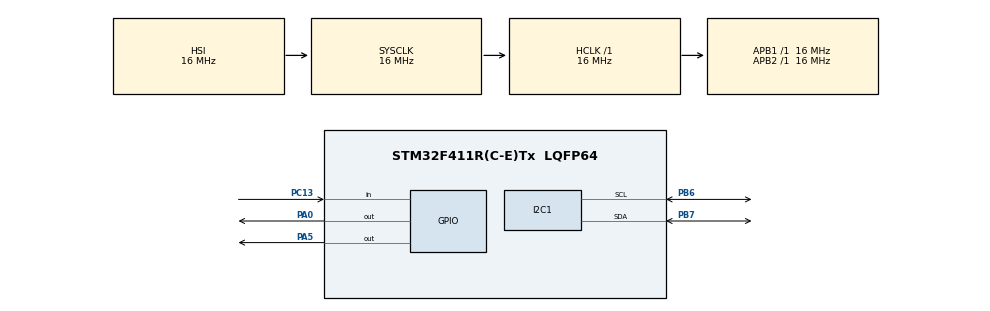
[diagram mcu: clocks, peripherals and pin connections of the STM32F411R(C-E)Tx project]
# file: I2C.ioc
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I2C1.AddressingMode=I2C_ADDRESSINGMODE_10BIT
I2C1.DutyCycle=I2C_DUTYCYCLE_16_9
I2C1.I2C_Mode=I2C_Fast
Mcu.Family=STM32F4
Mcu.Name=STM32F411R(C-E)Tx
Mcu.Package=LQFP64
NVIC.I2C1_ER_IRQn=true\:0\:0\:false
NVIC.I2C1_EV_IRQn=true\:0\:0\:false
NVIC.PriorityGroup=NVIC_PRIORITYGROUP_4
PA0-WKUP.GPIO_Speed=GPIO_SPEED_HIGH
PA0-WKUP.Signal=GPIO_Output
PA5.GPIO_Speed=GPIO_SPEED_HIGH
PA5.Signal=GPIO_Output
PB6.Mode=I2C
PB6.Signal=I2C1_SCL
PB7.Mode=I2C
PB7.Signal=I2C1_SDA
PC13-ANTI_TAMP.Signal=GPIO_Input
PH0\ -\ OSC_IN.Mode=HSE-External-Oscillator
PH0\ -\ OSC_IN.Signal=RCC_OSC_IN
PH1\ -\ OSC_OUT.Mode=HSE-External-Oscillator
PH1\ -\ OSC_OUT.Signal=RCC_OSC_OUT
ProjectManager.HeapSize=0x400
ProjectManager.StackSize=0x200
ProjectManager.TargetToolchain=MDK-ARM V5
RCC.AHBFreq_Value=16000000
RCC.APB1Freq_Value=16000000
RCC.APB2Freq_Value=16000000
RCC.CortexFreq_Value=16000000
RCC.HSE_VALUE=25000000
RCC.HSI_VALUE=16000000
RCC.LSE_VALUE=32768
RCC.SYSCLKFreq_VALUE=16000000
RCC.VCOOutputFreq_Value=192000000
board=I2C

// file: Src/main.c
/**
  ******************************************************************************
  * File Name          : main.c
  * Description        : Main program body
  ******************************************************************************
  *
  * COPYRIGHT(c) 2016 STMicroelectronics
  *
  * Redistribution and use in source and binary forms, with or without modification,
  * are permitted provided that the following conditions are met:
  *   1. Redistributions of source code must retain the above copyright notice,
  *      this list of conditions and the following disclaimer.
  *   2. Redistributions in binary form must reproduce the above copyright notice,
  *      this list of conditions and the following disclaimer in the documentation
  *      and/or other materials provided with the distribution.
  *   3. Neither the name of STMicroelectronics nor the names of its contributors
  *      may be used to endorse or promote products derived from this software
  *      without specific prior written permission.
  *
  * THIS SOFTWARE IS PROVIDED BY THE COPYRIGHT HOLDERS AND CONTRIBUTORS "AS IS"
  * AND ANY EXPRESS OR IMPLIED WARRANTIES, INCLUDING, BUT NOT LIMITED TO, THE
  * IMPLIED WARRANTIES OF MERCHANTABILITY AND FITNESS FOR A PARTICULAR PURPOSE ARE
  * DISCLAIMED. IN NO EVENT SHALL THE COPYRIGHT HOLDER OR CONTRIBUTORS BE LIABLE
  * FOR ANY DIRECT, INDIRECT, INCIDENTAL, SPECIAL, EXEMPLARY, OR CONSEQUENTIAL
  * DAMAGES (INCLUDING, BUT NOT LIMITED TO, PROCUREMENT OF SUBSTITUTE GOODS OR
  * SERVICES; LOSS OF USE, DATA, OR PROFITS; OR BUSINESS INTERRUPTION) HOWEVER
  * CAUSED AND ON ANY THEORY OF LIABILITY, WHETHER IN CONTRACT, STRICT LIABILITY,
  * OR TORT (INCLUDING NEGLIGENCE OR OTHERWISE) ARISING IN ANY WAY OUT OF THE USE
  * OF THIS SOFTWARE, EVEN IF ADVISED OF THE POSSIBILITY OF SUCH DAMAGE.
  *
  ******************************************************************************
  */
#include "stm32f4xx_hal.h"

I2C_HandleTypeDef hi2c1;

/* USER CODE BEGIN PV */
/* Private variables ---------------------------------------------------------*/
//#define MASTER_BOARD
#define I2C_ADDRESS			0x30F  // 0010 0000
uint8_t aTxBuffer[] = "Test I2C Communication";

uint8_t aRxBuffer[100];
/* USER CODE END PV */

void SystemClock_Config(void);
static void MX_GPIO_Init(void);
static void MX_I2C1_Init(void);

/* USER CODE BEGIN PFP */
/* Private function prototypes -----------------------------------------------*/

/* USER CODE END PFP */

int main(void)
{

  /* MCU Configuration----------------------------------------------------------*/

  /* Reset of all peripherals, Initializes the Flash interface and the Systick. */
  HAL_Init();

  /* Configure the system clock */
  SystemClock_Config();

  /* Initialize all configured peripherals */
  MX_GPIO_Init();
  MX_I2C1_Init();

  /* USER CODE BEGIN 2 */
/*
#ifdef MASTER_BOARD

	while(HAL_GPIO_ReadPin(GPIOC, GPIO_PIN_13) != 1)
	{
	}
	while(HAL_GPIO_ReadPin(GPIOC, GPIO_PIN_13) != 0)
	{
	}

	// Start the transmission process
	while(HAL_I2C_Master_Transmit(&hi2c1, (uint16_t)I2C_ADDRESS, (uint8_t *)aTxBuffer, 22, 10000) != HAL_OK)
	{
	}
	// turn on Led if transfer in transmission process in correct
	HAL_GPIO_WritePin(GPIOA, GPIO_PIN_0,  GPIO_PIN_RESET);
#else
*/
	// The board receives the message and sends it back
	if(HAL_I2C_Slave_Receive(&hi2c1, (uint8_t *)aRxBuffer, 22, 10000) != HAL_OK)
	{
		HAL_GPIO_WritePin(GPIOA, GPIO_PIN_0,  GPIO_PIN_SET);
	}
	HAL_GPIO_WritePin(GPIOA, GPIO_PIN_0,  GPIO_PIN_RESET);

//#endif
  /* USER CODE END 2 */

  /* Infinite loop */
  while (1)
  {
		HAL_I2C_Slave_Receive(&hi2c1, (uint8_t *)aRxBuffer, 22, 10000);

  }

}

/** System Clock Configuration
*/
void SystemClock_Config(void)
{

  RCC_OscInitTypeDef RCC_OscInitStruct;
  RCC_ClkInitTypeDef RCC_ClkInitStruct;

  __PWR_CLK_ENABLE();

  __HAL_PWR_VOLTAGESCALING_CONFIG(PWR_REGULATOR_VOLTAGE_SCALE1);

  RCC_OscInitStruct.OscillatorType = RCC_OSCILLATORTYPE_HSI;
  RCC_OscInitStruct.HSIState = RCC_HSI_ON;
  RCC_OscInitStruct.HSICalibrationValue = 16;
  RCC_OscInitStruct.PLL.PLLState = RCC_PLL_NONE;
  HAL_RCC_OscConfig(&RCC_OscInitStruct);

  RCC_ClkInitStruct.ClockType = RCC_CLOCKTYPE_HCLK|RCC_CLOCKTYPE_SYSCLK
                              |RCC_CLOCKTYPE_PCLK1|RCC_CLOCKTYPE_PCLK2;
  RCC_ClkInitStruct.SYSCLKSource = RCC_SYSCLKSOURCE_HSI;
  RCC_ClkInitStruct.AHBCLKDivider = RCC_SYSCLK_DIV1;
  RCC_ClkInitStruct.APB1CLKDivider = RCC_HCLK_DIV1;
  RCC_ClkInitStruct.APB2CLKDivider = RCC_HCLK_DIV1;
  HAL_RCC_ClockConfig(&RCC_ClkInitStruct, FLASH_LATENCY_0);

  HAL_SYSTICK_Config(HAL_RCC_GetHCLKFreq()/1000);

  HAL_SYSTICK_CLKSourceConfig(SYSTICK_CLKSOURCE_HCLK);

  /* SysTick_IRQn interrupt configuration */
  HAL_NVIC_SetPriority(SysTick_IRQn, 0, 0);
}

/* I2C1 init function */
void MX_I2C1_Init(void)
{

  hi2c1.Instance = I2C1;
  hi2c1.Init.ClockSpeed = 400000;
  hi2c1.Init.DutyCycle = I2C_DUTYCYCLE_16_9;
  hi2c1.Init.OwnAddress1 = 0;
  hi2c1.Init.AddressingMode = I2C_ADDRESSINGMODE_10BIT;
  hi2c1.Init.DualAddressMode = I2C_DUALADDRESS_DISABLED;
  hi2c1.Init.OwnAddress2 = 0;
  hi2c1.Init.GeneralCallMode = I2C_GENERALCALL_DISABLED;
  hi2c1.Init.NoStretchMode = I2C_NOSTRETCH_DISABLED;
  HAL_I2C_Init(&hi2c1);

}

/** Configure pins as
        * Analog
        * Input
        * Output
        * EVENT_OUT
        * EXTI
*/
void MX_GPIO_Init(void)
{

  GPIO_InitTypeDef GPIO_InitStruct;

  /* GPIO Ports Clock Enable */
  __GPIOC_CLK_ENABLE();
  __GPIOH_CLK_ENABLE();
  __GPIOA_CLK_ENABLE();
  __GPIOB_CLK_ENABLE();

  /*Configure GPIO pin : PC13 */
  GPIO_InitStruct.Pin = GPIO_PIN_13;
  GPIO_InitStruct.Mode = GPIO_MODE_INPUT;
  GPIO_InitStruct.Pull = GPIO_NOPULL;
  HAL_GPIO_Init(GPIOC, &GPIO_InitStruct);

  /*Configure GPIO pins : PA0 PA5 */
  GPIO_InitStruct.Pin = GPIO_PIN_0|GPIO_PIN_5;
  GPIO_InitStruct.Mode = GPIO_MODE_OUTPUT_PP;
  GPIO_InitStruct.Pull = GPIO_NOPULL;
  GPIO_InitStruct.Speed = GPIO_SPEED_HIGH;
  HAL_GPIO_Init(GPIOA, &GPIO_InitStruct);

  /*Configure GPIO pin Output Level */
  HAL_GPIO_WritePin(GPIOA, GPIO_PIN_0|GPIO_PIN_5, GPIO_PIN_RESET);

}

/************************ (C) COPYRIGHT STMicroelectronics *****END OF FILE****/
